# MCU_NAVSS0_UDMASS_RINGACC0_CFG_MON register map
Vendor: Texas Instruments
Peripheral module from a debugger description file (folder J7ES).
Registers are 32-bit, read-write, reset 0x0 unless marked. A register's access mark holds for its fields unless they carry their own. Offsets are as the file gives them; lines under a group give offsets from that group; [hi:lo] are bit positions; {n}, {i} and the like mark numbered series; 'fields as' and 'values as' point back to an identical list; <NAME> marks a mode.

## MCU_NAVSS0_UDMASS_RINGACC0_CFG_MON
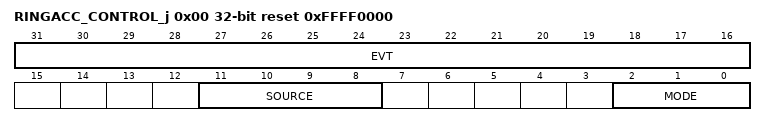
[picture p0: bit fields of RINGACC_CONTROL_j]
0x00 RINGACC_CONTROL_j reset 0xFFFF0000 — Monitor Control Register Offset = 0h + (j * 1000h); where j = 0h to 1Fh
  [31:16] EVT — Event to produce.
  [11:8] SOURCE — Monitor source selection. 0 = element count. 1 = head packet size (illegal for rings not in QM mode). 2 = accumulated queue size (illegal for rings not in QM mode).
  [2:0] MODE — Monitor Mode. 0 = disabled. 1 = push/pop statistics capture. 2 = low/high threshold checks. 3 = low/high watermarking. 4 = starvation counting.
0x04 RINGACC_QUEUE_j — Monitor Queue Register Offset = 4h + (j * 1000h); where j = 0h to 1Fh
  [15:0] VAL — Queue to monitor.
0x08 RINGACC_DATA0_j — Monitor Data Register Offset = 8h + (j * 1000h); where j = 0h to 1Fh
  [31:0] VAL — Monitor Data. For mode 1 this is read-only and number of pushes. For mode 2 this is read-write and the low threshold value. For mode 3 this is read only and the low watermark. For mode 4 this is read only and the starvation count.
0x0C RINGACC_DATA1_j — Monitor Data Register Offset = Ch + (j * 1000h); where j = 0h to 1Fh
  [31:0] VAL — Monitor Data. For mode 1 this is read-only and number of pops. For mode 2 this is read-write and the high threshold value. For mode 3 this is read only and the high watermark. For mode 4 this is not used.
